# PIC18F16Q41 register map
Vendor: Microchip
Registers are 8-bit, read-write, reset 0x0 unless marked. A register's access mark holds for its fields unless they carry their own. Addresses are absolute, and some are shared; only a register's first bit layout is shown; [hi:lo] are bit positions; {n}, {i} and the like mark numbered series.

## opamp_v7_KV00F
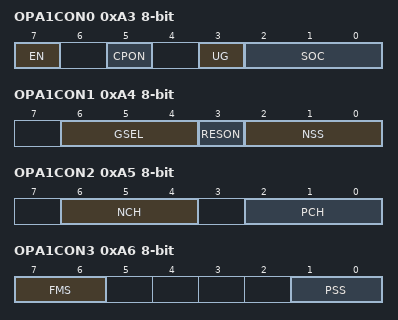
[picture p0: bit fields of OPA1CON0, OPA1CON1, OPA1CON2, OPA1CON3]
0xA3 OPA1CON0
  [7] EN, [5] CPON, [3] UG, [2:0] SOC
0xA4 OPA1CON1
  [6:4] GSEL, [3] RESON, [2:0] NSS
0xA5 OPA1CON2
  [6:4] NCH, [2:0] PCH
0xA6 OPA1CON3 reset not defined — (power-on value 00----xx)
  [7:6] FMS, [1:0] PSS
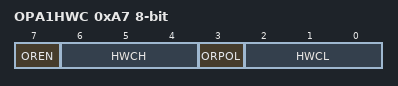
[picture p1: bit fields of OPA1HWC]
0xA7 OPA1HWC
  [7] OREN, [6:4] HWCH, [3] ORPOL, [2:0] HWCL
0xA8 OPA1OFFSET
  [7:0] OFFSET
0xA9 OPA1ORS
  [4:0] ORS

## cla_clc
0xD5 CLCSELECT
  [1:0] SLCT
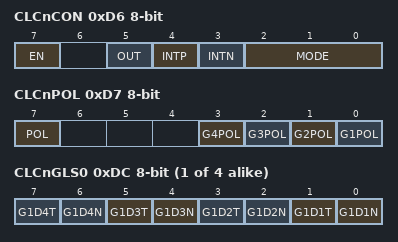
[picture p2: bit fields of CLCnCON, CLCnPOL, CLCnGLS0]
0xD6 CLCnCON — Configurable logic cell control
  [7] EN, [5] OUT ro, [4] INTP, [3] INTN, [2:0] MODE
0xD7 CLCnPOL reset not defined — Polarity control (power-on value 0---xxxx)
  [7] POL, [n-1] G{n}POL (n=1..4)
{0xD8+i} CLCnSEL{i} reset not defined (i=0..3) — Input select register 1 (power-on value -xxxxxxx)
  [6:0] D{i+1}S
{0xDC+i} CLCnGLS{i} reset not defined (i=0..3) — Gate logic select register {i} (power-on value xxxxxxxx)
  [2n-1] G{i+1}D{n}T (n=1..4), [2n-2] G{i+1}D{n}N (n=1..4)

## dma
0xE8 DMASELECT — DMA instance selection register
  [1:0] SLCT
0xE9 DMAnBUF ro reset not defined — DMA data buffer (power-on value xxxxxxxx)
  [7:0] BUF
0xEA DMAnDCNTL
  [7:0] DCNT
0xEB DMAnDCNTH
  [3:0] DCNT
0xEC DMAnDPTRL ro
  [7:0] DPTR
0xED DMAnDPTRH ro
  [7:0] DPTR
0xEE DMAnDSZL reset not defined — (power-on value xxxxxxxx)
  [7:0] DSZ
0xEF DMAnDSZH
  [3:0] DSZ
0xF0 DMAnDSAL reset not defined — (power-on value xxxxxxxx)
  [7:0] DSA
0xF1 DMAnDSAH
  [7:0] DSA
0xF2 DMAnSCNTL
  [7:0] SCNT
0xF3 DMAnSCNTH
  [3:0] SCNT
0xF4 DMAnSPTRL ro
  [7:0] SPTR
0xF5 DMAnSPTRH ro
  [7:0] SPTR
0xF6 DMAnSPTRU ro
  [5:0] SPTR
0xF7 DMAnSSZL
  [7:0] SSZ
0xF8 DMAnSSZH
  [3:0] SSZ
0xF9 DMAnSSAL
  [7:0] SSA
0xFA DMAnSSAH
  [7:0] SSA
0xFB DMAnSSAU
  [5:0] SSA
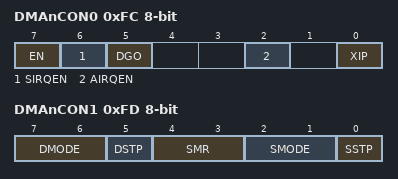
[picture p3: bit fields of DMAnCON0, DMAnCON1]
0xFC DMAnCON0 — DMA control register 0
  [7] EN, [6] SIRQEN, [5] DGO, [2] AIRQEN, [0] XIP ro
0xFD DMAnCON1 — DMA control register 1
  [7:6] DMODE, [5] DSTP, [4:3] SMR, [2:1] SMODE, [0] SSTP
0xFE DMAnAIRQ — DMA abort trigger selection register
  [6:0] AIRQ
0xFF DMAnSIRQ — DMA start trigger selection register
  [6:0] SIRQ

## DOS_xxxxx_pps_mid_v2_output_8bit
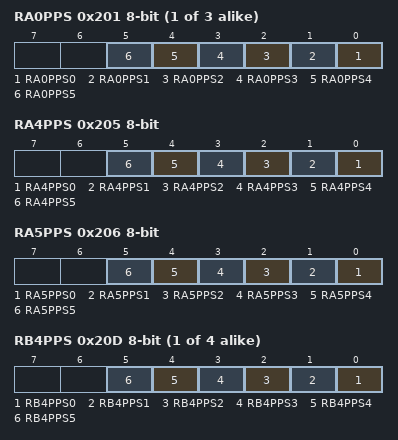
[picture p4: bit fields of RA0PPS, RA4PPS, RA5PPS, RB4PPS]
{0x201+i} RA{i}PPS (i=0..2)
  [n] RA{i}PPS{n} (n=0..5)
0x205 RA4PPS
  [n] RA4PPS{n} (n=0..5)
0x206 RA5PPS
  [n] RA5PPS{n} (n=0..5)
{0x209+i} RB{i}PPS (i=4..7)
  [n] RB{i}PPS{n} (n=0..5)
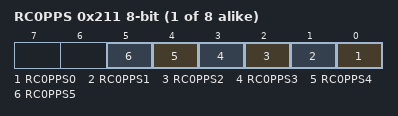
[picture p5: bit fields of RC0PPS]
{0x211+i} RC{i}PPS (i=0..7)
  [n] RC{i}PPS{n} (n=0..5)

## DOS_xxxx_pps_mid
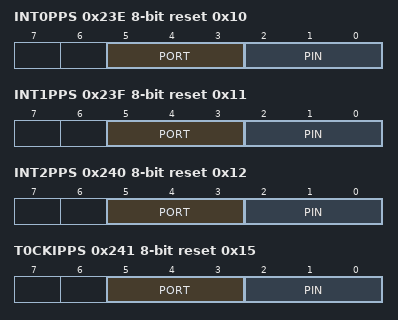
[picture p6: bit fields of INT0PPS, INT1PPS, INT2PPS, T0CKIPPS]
0x23E INT0PPS reset 0x10
  [5:3] PORT, [2:0] PIN
0x23F INT1PPS reset 0x11
  [5:3] PORT, [2:0] PIN
0x240 INT2PPS reset 0x12
  [5:3] PORT, [2:0] PIN
0x241 T0CKIPPS reset 0x15
  [5:3] PORT, [2:0] PIN
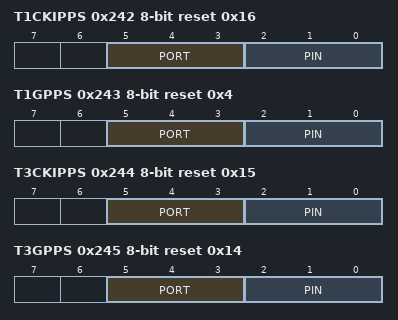
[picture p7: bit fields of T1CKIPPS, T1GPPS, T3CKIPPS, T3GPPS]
0x242 T1CKIPPS reset 0x16
  [5:3] PORT, [2:0] PIN
0x243 T1GPPS reset 0x4
  [5:3] PORT, [2:0] PIN
0x244 T3CKIPPS reset 0x15
  [5:3] PORT, [2:0] PIN
0x245 T3GPPS reset 0x14
  [5:3] PORT, [2:0] PIN
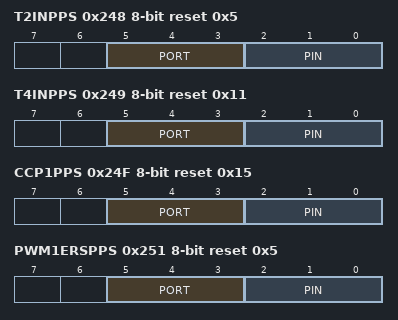
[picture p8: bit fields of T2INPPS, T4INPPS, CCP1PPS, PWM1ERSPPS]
0x248 T2INPPS reset 0x5
  [5:3] PORT, [2:0] PIN
0x249 T4INPPS reset 0x11
  [5:3] PORT, [2:0] PIN
0x24F CCP1PPS reset 0x15
  [5:3] PORT, [2:0] PIN
0x251 PWM1ERSPPS reset 0x5
  [5:3] PORT, [2:0] PIN
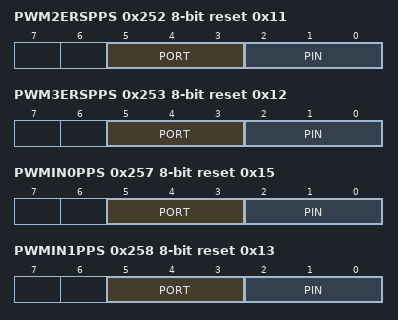
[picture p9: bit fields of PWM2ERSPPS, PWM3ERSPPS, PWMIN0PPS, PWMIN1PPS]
0x252 PWM2ERSPPS reset 0x11
  [5:3] PORT, [2:0] PIN
0x253 PWM3ERSPPS reset 0x12
  [5:3] PORT, [2:0] PIN
0x257 PWMIN0PPS reset 0x15
  [5:3] PORT, [2:0] PIN
0x258 PWMIN1PPS reset 0x13
  [5:3] PORT, [2:0] PIN
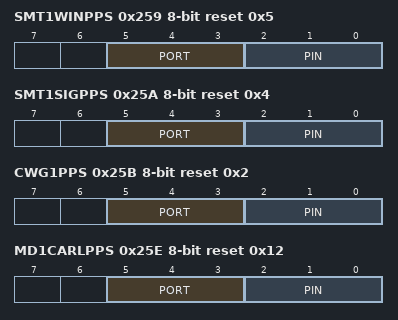
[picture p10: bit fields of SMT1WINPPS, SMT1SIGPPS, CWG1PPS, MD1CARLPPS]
0x259 SMT1WINPPS reset 0x5
  [5:3] PORT, [2:0] PIN
0x25A SMT1SIGPPS reset 0x4
  [5:3] PORT, [2:0] PIN
0x25B CWG1PPS reset 0x2
  [5:3] PORT, [2:0] PIN
0x25E MD1CARLPPS reset 0x12
  [5:3] PORT, [2:0] PIN
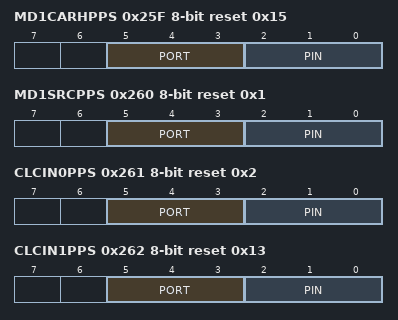
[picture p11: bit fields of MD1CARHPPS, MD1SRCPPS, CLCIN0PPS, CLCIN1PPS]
0x25F MD1CARHPPS reset 0x15
  [5:3] PORT, [2:0] PIN
0x260 MD1SRCPPS reset 0x1
  [5:3] PORT, [2:0] PIN
0x261 CLCIN0PPS reset 0x2
  [5:3] PORT, [2:0] PIN
0x262 CLCIN1PPS reset 0x13
  [5:3] PORT, [2:0] PIN
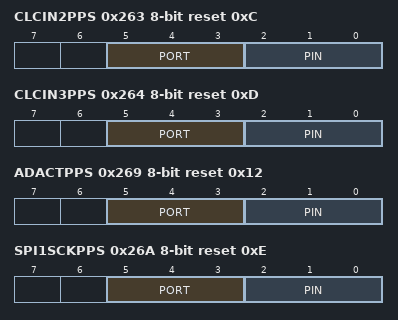
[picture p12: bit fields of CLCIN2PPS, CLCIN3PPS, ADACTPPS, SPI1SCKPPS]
0x263 CLCIN2PPS reset 0xC
  [5:3] PORT, [2:0] PIN
0x264 CLCIN3PPS reset 0xD
  [5:3] PORT, [2:0] PIN
0x269 ADACTPPS reset 0x12
  [5:3] PORT, [2:0] PIN
0x26A SPI1SCKPPS reset 0xE
  [5:3] PORT, [2:0] PIN
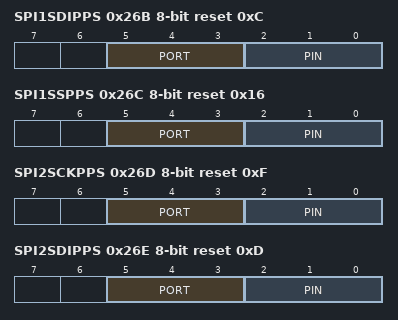
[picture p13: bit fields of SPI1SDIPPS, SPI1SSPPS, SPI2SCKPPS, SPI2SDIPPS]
0x26B SPI1SDIPPS reset 0xC
  [5:3] PORT, [2:0] PIN
0x26C SPI1SSPPS reset 0x16
  [5:3] PORT, [2:0] PIN
0x26D SPI2SCKPPS reset 0xF
  [5:3] PORT, [2:0] PIN
0x26E SPI2SDIPPS reset 0xD
  [5:3] PORT, [2:0] PIN
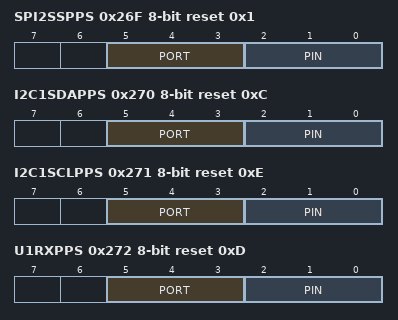
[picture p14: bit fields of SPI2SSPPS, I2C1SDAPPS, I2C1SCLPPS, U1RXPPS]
0x26F SPI2SSPPS reset 0x1
  [5:3] PORT, [2:0] PIN
0x270 I2C1SDAPPS reset 0xC
  [5:3] PORT, [2:0] PIN
0x271 I2C1SCLPPS reset 0xE
  [5:3] PORT, [2:0] PIN
0x272 U1RXPPS reset 0xD
  [5:3] PORT, [2:0] PIN
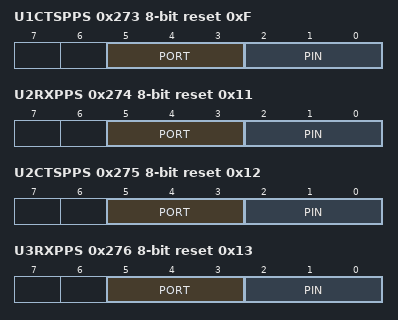
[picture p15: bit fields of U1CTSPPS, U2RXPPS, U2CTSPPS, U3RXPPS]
0x273 U1CTSPPS reset 0xF
  [5:3] PORT, [2:0] PIN
0x274 U2RXPPS reset 0x11
  [5:3] PORT, [2:0] PIN
0x275 U2CTSPPS reset 0x12
  [5:3] PORT, [2:0] PIN
0x276 U3RXPPS reset 0x13
  [5:3] PORT, [2:0] PIN
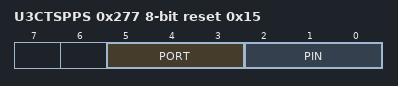
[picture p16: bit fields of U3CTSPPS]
0x277 U3CTSPPS reset 0x15
  [5:3] PORT, [2:0] PIN
